AUTOSAR XML (schema 4-3-0)
package /ComponentTypes
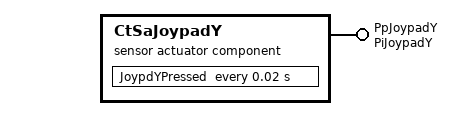
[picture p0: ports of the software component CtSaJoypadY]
  sensor actuator sw component type CtSaJoypadY
    provide port PpJoypadY: nonqueued-sender-com-spec{data-element=DeJoypadY, init-value=0}, provided-interface=PiJoypadY
    behavior CtSaJoypadY_InternalBehavior
      timing event TMT_JoypdYPressed: start-on-event=JoypdYPressed, period=0.02
      runnable JoypdYPressed
        data-send-points:
          access SEND_PpJoypadY_DeJoypadY: accessed-variable=PpJoypadY.DeJoypadY
  swc implementation CtSaJoypadY_Implementation: behavior=CtSaJoypadY_InternalBehavior
